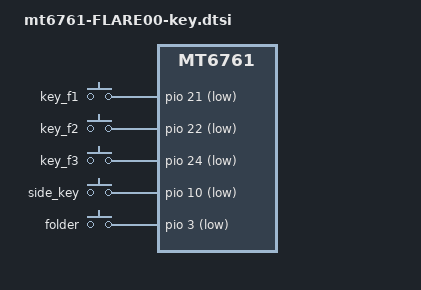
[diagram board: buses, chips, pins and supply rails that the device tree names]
/*
 * This software is contributed or developed by KYOCERA Corporation.
 * (C) 2021 KYOCERA Corporation
 *
 * This program is free software; you can redistribute it and/or modify
 * it under the terms of the GNU General Public License version 2 and
 * only version 2 as published by the Free Software Foundation.
 *
 * This program is distributed in the hope that it will be useful,
 * but WITHOUT ANY WARRANTY; without even the implied warranty of
 * MERCHANTABILITY or FITNESS FOR A PARTICULAR PURPOSE.  See the
 * GNU General Public License for more details.
 */

#include <dt-bindings/pinctrl/mt6761-pinfunc.h>

&pio {
	gpio_keys_default: gpio_keys_default {
		pins_cmd0_dat {
			pinmux = <PINMUX_GPIO21__FUNC_GPIO21>;
			slew-rate = <0>;
			bias-pull-up;
		};
		pins_cmd1_dat {
			pinmux = <PINMUX_GPIO22__FUNC_GPIO22>;
			slew-rate = <0>;
			bias-pull-up;
		};
		pins_cmd2_dat {
			pinmux = <PINMUX_GPIO24__FUNC_GPIO24>;
			slew-rate = <0>;
			bias-pull-up;
		};
		pins_cmd3_dat {
			pinmux = <PINMUX_GPIO10__FUNC_GPIO10>;
			slew-rate = <0>;
			bias-pull-up;
		};
		pins_cmd4_dat {
			pinmux = <PINMUX_GPIO3__FUNC_GPIO3>;
			slew-rate = <0>;
			bias-pull-up;
		};
	};
};

&odm {
	gpio_keys {
		compatible = "gpio-keys";
		input-name = "gpio-keys";
		label = "gpio-keys";
		pinctrl-names = "default";
		pinctrl-0 = <&gpio_keys_default>;

		key_f1 {
			label = "key_f1";
			gpios = <&pio 21 1>;
			linux,input-type = <0x1>;
			linux,code = <0x3F>;	/* KEY_F5[63] */
			debounce-interval = <20>;
			linux,can-disable;
			gpio-key,wakeup;
			on_chattering_num  = <1>;
			off_chattering_num = <0>;
		};

		key_f2 {
			label = "key_f2";
			gpios = <&pio 22 1>;
			linux,input-type = <0x1>;
			linux,code = <0x40>;	/* KEY_F6[64] */
			debounce-interval = <20>;
			linux,can-disable;
			gpio-key,wakeup;
			on_chattering_num  = <1>;
			off_chattering_num = <0>;
		};

		key_f3 {
			label = "key_f3";
			gpios = <&pio 24 1>;
			linux,input-type = <0x1>;
			linux,code = <0x41>;	/* KEY_F7[65] */
			debounce-interval = <20>;
			linux,can-disable;
			gpio-key,wakeup;
			on_chattering_num  = <1>;
			off_chattering_num = <0>;
		};

		side_key {
			label = "side_key";
			gpios = <&pio 10 1>;
			linux,input-type = <0x1>;
			linux,code = <0xFE>;	/* KEY_SIDE[254] */
			debounce-interval = <20>;
			linux,can-disable;
			gpio-key,wakeup;
			on_chattering_num  = <1>;
			off_chattering_num = <0>;
		};

		folder {
			label = "folder";
			gpios = <&pio 3 1>;
			linux,input-type = <5>;
			linux,code = <0x00>;	/* SW_LID */
			debounce-interval = <25>;
			linux,can-disable;
			gpio-key,wakeup;
			on_chattering_num  = <1>;
			off_chattering_num = <1>;
		};
	};
};

&keypad {
	mediatek,kpd-sw-rstkey-cust = <522>;
};

